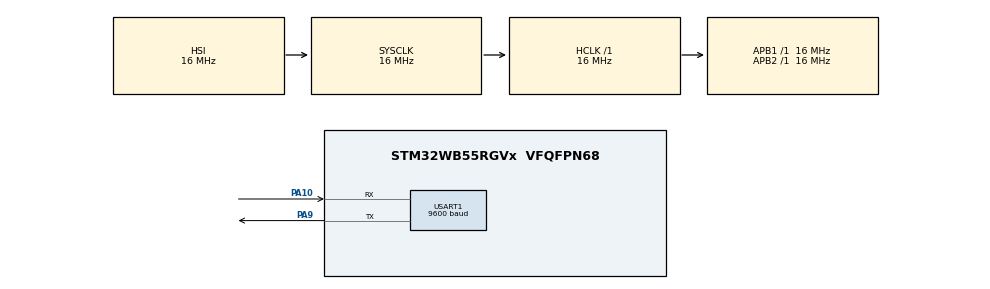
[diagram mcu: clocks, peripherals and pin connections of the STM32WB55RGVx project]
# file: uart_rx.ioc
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Mcu.Family=STM32WB
Mcu.Name=STM32WB55RGVx
Mcu.Package=VFQFPN68
NVIC.PriorityGroup=NVIC_PRIORITYGROUP_4
PA10.Mode=Asynchronous
PA10.Signal=USART1_RX
PA9.Mode=Asynchronous
PA9.Signal=USART1_TX
ProjectManager.HeapSize=0x200
ProjectManager.StackSize=0x400
ProjectManager.TargetToolchain=STM32CubeIDE
RCC.ADCFreq_Value=64000000
RCC.AHBFreq_Value=16000000
RCC.APB1Freq_Value=16000000
RCC.APB1TimFreq_Value=16000000
RCC.APB2Freq_Value=16000000
RCC.APB2TimFreq_Value=16000000
RCC.APB3Freq_Value=16000000
RCC.CortexFreq_Value=16000000
RCC.HCLKFreq_Value=16000000
RCC.HSE_VALUE=8000000
RCC.HSI48_VALUE=48000000
RCC.HSI_VALUE=16000000
RCC.LSE_VALUE=32768
RCC.PLLSourceVirtual=RCC_PLLSOURCE_HSI
RCC.SYSCLKFreq_VALUE=16000000
RCC.SYSCLKSource=RCC_SYSCLKSOURCE_HSI
RCC.USBFreq_Value=64000000
RCC.VCOOutputFreq_Value=128000000
USART1.BaudRate=9600
USART1.VirtualMode-Asynchronous=VM_ASYNC
VP_MEMORYMAP_VS_MEMORYMAP.Mode=CurAppReg
board=custom

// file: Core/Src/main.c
/* USER CODE BEGIN Header */
/**
  ******************************************************************************
  * @file           : main.c
  * @brief          : Main program body
  ******************************************************************************
  * @attention
  *
  * Copyright (c) 2025 STMicroelectronics.
  * All rights reserved.
  *
  * This software is licensed under terms that can be found in the LICENSE file
  * in the root directory of this software component.
  * If no LICENSE file comes with this software, it is provided AS-IS.
  *
  ******************************************************************************
  */
/* USER CODE END Header */
#include "main.h"
#include<string.h>

UART_HandleTypeDef huart1;

void SystemClock_Config(void);
void PeriphCommonClock_Config(void);
static void MX_GPIO_Init(void);
static void MX_USART1_UART_Init(void);

int main(void)
{

  /* MCU Configuration--------------------------------------------------------*/

  /* Reset of all peripherals, Initializes the Flash interface and the Systick. */
  HAL_Init();

  /* Configure the system clock */
  SystemClock_Config();

  /* Configure the peripherals common clocks */
  PeriphCommonClock_Config();

  /* Initialize all configured peripherals */
  MX_GPIO_Init();
  MX_USART1_UART_Init();
  /* USER CODE BEGIN 2 */

  /*uart code with interrupt*/
  uint8_t tx = 'A';
  uint8_t rx_data,index;
  uint8_t rx_buffer[50];
  char msg[] = "Hello World\r\n";

  /*uart code with interrupt*/

  /* USER CODE END 2 */

  /* Infinite loop */
  while (1)
  {
	  //HAL_UART_Transmit(&huart1,&tx, 1, HAL_MAX_DELAY);
	  HAL_UART_Transmit(&huart1, (uint8_t*)msg, strlen(msg), HAL_MAX_DELAY);
	  HAL_Delay(1000); // Optional delay
	 //	  tx++;

  }
}

void SystemClock_Config(void)
{
  RCC_OscInitTypeDef RCC_OscInitStruct = {0};
  RCC_ClkInitTypeDef RCC_ClkInitStruct = {0};

  /** Configure the main internal regulator output voltage
  */
  __HAL_PWR_VOLTAGESCALING_CONFIG(PWR_REGULATOR_VOLTAGE_SCALE1);

  /** Initializes the RCC Oscillators according to the specified parameters
  * in the RCC_OscInitTypeDef structure.
  */
  RCC_OscInitStruct.OscillatorType = RCC_OSCILLATORTYPE_HSI;
  RCC_OscInitStruct.HSIState = RCC_HSI_ON;
  RCC_OscInitStruct.HSICalibrationValue = RCC_HSICALIBRATION_DEFAULT;
  RCC_OscInitStruct.PLL.PLLState = RCC_PLL_NONE;
  if (HAL_RCC_OscConfig(&RCC_OscInitStruct) != HAL_OK)
  {
    Error_Handler();
  }

  /** Configure the SYSCLKSource, HCLK, PCLK1 and PCLK2 clocks dividers
  */
  RCC_ClkInitStruct.ClockType = RCC_CLOCKTYPE_HCLK4|RCC_CLOCKTYPE_HCLK2
                              |RCC_CLOCKTYPE_HCLK|RCC_CLOCKTYPE_SYSCLK
                              |RCC_CLOCKTYPE_PCLK1|RCC_CLOCKTYPE_PCLK2;
  RCC_ClkInitStruct.SYSCLKSource = RCC_SYSCLKSOURCE_HSI;
  RCC_ClkInitStruct.AHBCLKDivider = RCC_SYSCLK_DIV1;
  RCC_ClkInitStruct.APB1CLKDivider = RCC_HCLK_DIV1;
  RCC_ClkInitStruct.APB2CLKDivider = RCC_HCLK_DIV1;
  RCC_ClkInitStruct.AHBCLK2Divider = RCC_SYSCLK_DIV1;
  RCC_ClkInitStruct.AHBCLK4Divider = RCC_SYSCLK_DIV1;

  if (HAL_RCC_ClockConfig(&RCC_ClkInitStruct, FLASH_LATENCY_0) != HAL_OK)
  {
    Error_Handler();
  }
}

void PeriphCommonClock_Config(void)
{
  RCC_PeriphCLKInitTypeDef PeriphClkInitStruct = {0};

  /** Initializes the peripherals clock
  */
  PeriphClkInitStruct.PeriphClockSelection = RCC_PERIPHCLK_SMPS;
  PeriphClkInitStruct.SmpsClockSelection = RCC_SMPSCLKSOURCE_HSI;
  PeriphClkInitStruct.SmpsDivSelection = RCC_SMPSCLKDIV_RANGE1;

  if (HAL_RCCEx_PeriphCLKConfig(&PeriphClkInitStruct) != HAL_OK)
  {
    Error_Handler();
  }
}

static void MX_USART1_UART_Init(void)
{

  huart1.Instance = USART1;
  huart1.Init.BaudRate = 9600;
  huart1.Init.WordLength = UART_WORDLENGTH_8B;
  huart1.Init.StopBits = UART_STOPBITS_1;
  huart1.Init.Parity = UART_PARITY_NONE;
  huart1.Init.Mode = UART_MODE_TX_RX;
  huart1.Init.HwFlowCtl = UART_HWCONTROL_NONE;
  huart1.Init.OverSampling = UART_OVERSAMPLING_16;
  huart1.Init.OneBitSampling = UART_ONE_BIT_SAMPLE_DISABLE;
  huart1.Init.ClockPrescaler = UART_PRESCALER_DIV1;
  huart1.AdvancedInit.AdvFeatureInit = UART_ADVFEATURE_NO_INIT;
  if (HAL_UART_Init(&huart1) != HAL_OK)
  {
    Error_Handler();
  }
  if (HAL_UARTEx_SetTxFifoThreshold(&huart1, UART_TXFIFO_THRESHOLD_1_8) != HAL_OK)
  {
    Error_Handler();
  }
  if (HAL_UARTEx_SetRxFifoThreshold(&huart1, UART_RXFIFO_THRESHOLD_1_8) != HAL_OK)
  {
    Error_Handler();
  }
  if (HAL_UARTEx_DisableFifoMode(&huart1) != HAL_OK)
  {
    Error_Handler();
  }

}

static void MX_GPIO_Init(void)
{

  /* GPIO Ports Clock Enable */
  __HAL_RCC_GPIOA_CLK_ENABLE();

}

void Error_Handler(void)
{
  __disable_irq();
  while (1)
  {
  }
}
